# CBASS_CBASS_ISC_45820000h register map
Vendor: Texas Instruments
Peripheral module from a debugger description file (folder AM275x).
Registers are 32-bit, read-write, reset 0x0 unless marked. A register's access mark holds for its fields unless they carry their own. Offsets are as the file gives them; lines under a group give offsets from that group; [hi:lo] are bit positions; {n}, {i} and the like mark numbered series; 'fields as' and 'values as' point back to an identical list; <NAME> marks a mode.

## cbass_isc
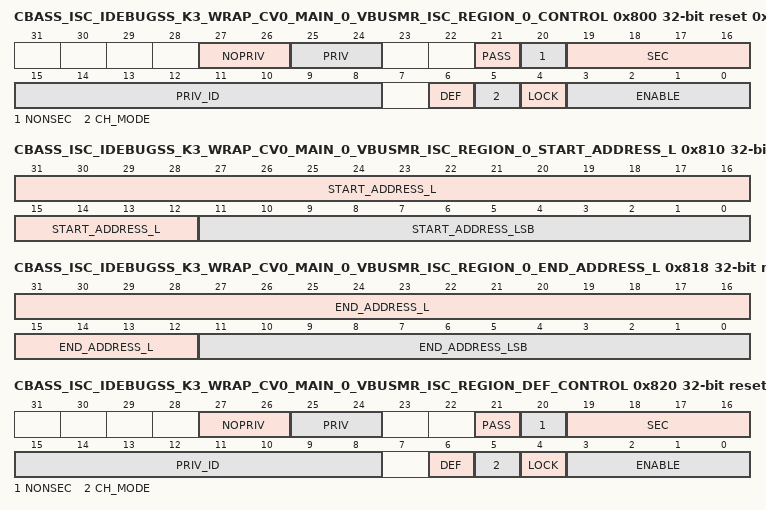
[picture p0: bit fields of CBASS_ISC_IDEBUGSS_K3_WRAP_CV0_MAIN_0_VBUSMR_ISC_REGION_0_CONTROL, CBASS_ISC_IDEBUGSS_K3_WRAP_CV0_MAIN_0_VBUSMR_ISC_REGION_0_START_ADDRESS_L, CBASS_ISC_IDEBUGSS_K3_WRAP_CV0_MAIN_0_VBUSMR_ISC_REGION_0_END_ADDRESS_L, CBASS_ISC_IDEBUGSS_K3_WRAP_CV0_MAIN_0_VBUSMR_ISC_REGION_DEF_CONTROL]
0x800 CBASS_ISC_IDEBUGSS_K3_WRAP_CV0_MAIN_0_VBUSMR_ISC_REGION_0_CONTROL access not given reset 0x10B100 — The ISC Region 0 Control Register defines the control fields for the initiator Idebugss_k3_wrap_cv0_main_0.vbusmr region 0 ISC.
  [27:26] NOPRIV rw — Clear output priv attribute. If each bit is set then the outgoing priv bit is cleared. Reset Source: domain_default_rst_mod_g_rst_n
  [25:24] PRIV rw — Set outgoing priv attribute. If each bit is set then the outgoing priv bit is set. Reset Source: domain_default_rst_mod_g_rst_n
  [21] PASS rw — No privID replacement, pass through value. Reset Source: domain_default_rst_mod_g_rst_n
  [20] NONSEC rw — Make outgoing non-secure. Reset Source: domain_default_rst_mod_g_rst_n
  [19:16] SEC rw — Make outgoing secure. A value of 0xA enables, others disable. Reset Source: domain_default_rst_mod_g_rst_n
  [15:8] PRIV_ID rw — Priv ID. Reset Source: domain_default_rst_mod_g_rst_n
  [6] DEF ro — Default region indication. The default region is used when all other regions do not match. Reset Source: domain_default_rst_mod_g_rst_n
  [5] CH_MODE rw — Enable channel mode to match region to a chanid value. Otherwise use address mode to match region to an address range. Reset Source: domain_default_rst_mod_g_rst_n
  [4] LOCK — Lock region. Once set the region values cannot be modified. Reset Source: domain_default_rst_mod_g_rst_n (access R/W1TS)
  [3:0] ENABLE rw — Enable region. A value of 0xA enables, others disable. Reset Source: domain_default_rst_mod_g_rst_n
0x810 CBASS_ISC_IDEBUGSS_K3_WRAP_CV0_MAIN_0_VBUSMR_ISC_REGION_0_START_ADDRESS_L — The ISC Region 0 Start Address Low Register defines the start address bits 31 to 0 for the initiator Idebugss_k3_wrap_cv0_main_0.vbusmr region 0 ISC.
  [31:12] START_ADDRESS_L — Start address bits 31 to 12. Reset Source: domain_default_rst_mod_g_rst_n
  [11:0] START_ADDRESS_LSB — Start address bits 11 to 0 must be 0 as address must be 4KB aligned in address mode. Can also be channel number in channel mode. Reset Source: domain_default_rst_mod_g_rst_n
0x814 CBASS_ISC_IDEBUGSS_K3_WRAP_CV0_MAIN_0_VBUSMR_ISC_REGION_0_START_ADDRESS_H — The ISC Region 0 Start Address High Register defines the start address bits 47 to 32 for the initiator Idebugss_k3_wrap_cv0_main_0.vbusmr region 0 ISC.
  [15:0] START_ADDRESS_H — Start address bits 47 to 32. Reset Source: domain_default_rst_mod_g_rst_n
0x818 CBASS_ISC_IDEBUGSS_K3_WRAP_CV0_MAIN_0_VBUSMR_ISC_REGION_0_END_ADDRESS_L access per field reset 0xFFF — The ISC Region 0 End Address Low Register defines the end included address bits 31 to 0 for the initiator Idebugss_k3_wrap_cv0_main_0.vbusmr region 0 ISC.
  [31:12] END_ADDRESS_L rw — End address bits 31 to 12 to include in the match. Reset Source: domain_default_rst_mod_g_rst_n
  [11:0] END_ADDRESS_LSB ro — End address bits 11 to 0 are forced to Fs as address must be 4KB aligned. Reset Source: domain_default_rst_mod_g_rst_n
0x81C CBASS_ISC_IDEBUGSS_K3_WRAP_CV0_MAIN_0_VBUSMR_ISC_REGION_0_END_ADDRESS_H — The ISC Region 0 End Address High Register defines the end address bits 47 to 32 for the initiator Idebugss_k3_wrap_cv0_main_0.vbusmr region 0 ISC.
  [15:0] END_ADDRESS_H — End address bits 47 to 32. Reset Source: domain_default_rst_mod_g_rst_n
0x820 CBASS_ISC_IDEBUGSS_K3_WRAP_CV0_MAIN_0_VBUSMR_ISC_REGION_DEF_CONTROL access not given reset 0x10B14A — The ISC Default Region Control Register defines the control fields for the initiator Idebugss_k3_wrap_cv0_main_0.vbusmr region 1 ISC.
  [27:26] NOPRIV rw — Clear output priv attribute. If each bit is set then the outgoing priv bit is cleared, else the bit is unchanged. Do not set both priv and nopriv for the same bit. Reset Source: domain_default_rst_mod_g_rst_n
  [25:24] PRIV rw — Set outgoing priv attribute. If each bit is set then the outgoing priv bit is set, else the bit is unchanged. Do not set both priv and nopriv for the same bit. Reset Source: domain_default_rst_mod_g_rst_n
  [21] PASS rw — No privID replacement. A value of 1 will pass through privid value. A value of 0 will replace privid with priv_id field value. Reset Source: domain_default_rst_mod_g_rst_n
  [20] NONSEC rw — Make outgoing non-secure. A value of 1 forces secure clear, others do nothing. Do not set both sec and nonsec. Reset Source: domain_default_rst_mod_g_rst_n
  [19:16] SEC rw — Make outgoing secure. A value of 0xA forces secure set, others do nothing. Do not set both sec and nonsec. Reset Source: domain_default_rst_mod_g_rst_n
  [15:8] PRIV_ID rw — Priv ID value to use if pass is 0. Reset Source: domain_default_rst_mod_g_rst_n
  [6] DEF ro — Default region indication. The default region is used when all other regions do not match. Reset Source: domain_default_rst_mod_g_rst_n
  [5] CH_MODE ro — Enable channel mode to match region to a chanid value. Otherwise use address mode to match region to an address range. Reset Source: domain_default_rst_mod_g_rst_n
  [4] LOCK — Lock region. Once set, the region values cannot be modified. Reset Source: domain_default_rst_mod_g_rst_n (access R/W1TS)
  [3:0] ENABLE ro — Enable region. A value of 0xA enables, others disable. Reset Source: domain_default_rst_mod_g_rst_n
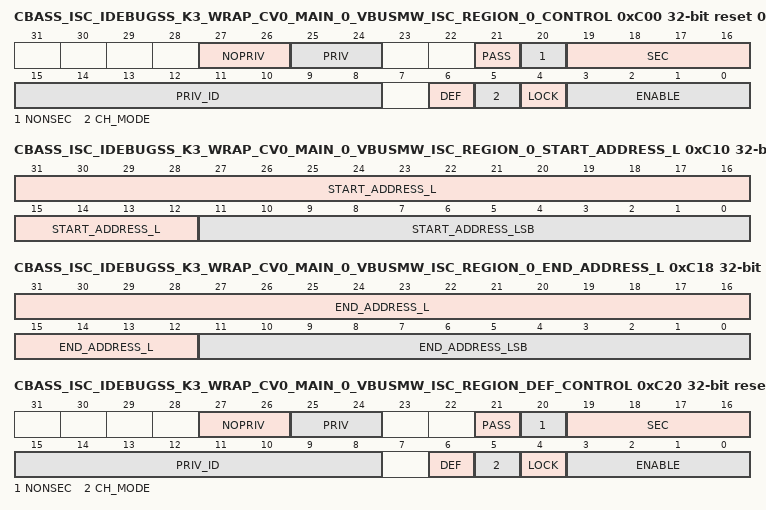
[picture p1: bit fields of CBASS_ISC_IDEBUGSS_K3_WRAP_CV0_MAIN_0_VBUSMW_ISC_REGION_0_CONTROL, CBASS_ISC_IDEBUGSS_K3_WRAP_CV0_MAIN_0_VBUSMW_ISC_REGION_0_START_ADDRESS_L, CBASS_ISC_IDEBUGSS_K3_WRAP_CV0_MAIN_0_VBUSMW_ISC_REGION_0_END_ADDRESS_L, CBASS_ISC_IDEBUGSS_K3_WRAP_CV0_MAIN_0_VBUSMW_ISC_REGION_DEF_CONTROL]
0xC00 CBASS_ISC_IDEBUGSS_K3_WRAP_CV0_MAIN_0_VBUSMW_ISC_REGION_0_CONTROL access not given reset 0x10B100 — The ISC Region 0 Control Register defines the control fields for the initiator Idebugss_k3_wrap_cv0_main_0.vbusmw region 0 ISC.
  fields as CBASS_ISC_IDEBUGSS_K3_WRAP_CV0_MAIN_0_VBUSMR_ISC_REGION_0_CONTROL
0xC10 CBASS_ISC_IDEBUGSS_K3_WRAP_CV0_MAIN_0_VBUSMW_ISC_REGION_0_START_ADDRESS_L — The ISC Region 0 Start Address Low Register defines the start address bits 31 to 0 for the initiator Idebugss_k3_wrap_cv0_main_0.vbusmw region 0 ISC.
  fields as CBASS_ISC_IDEBUGSS_K3_WRAP_CV0_MAIN_0_VBUSMR_ISC_REGION_0_START_ADDRESS_L
0xC14 CBASS_ISC_IDEBUGSS_K3_WRAP_CV0_MAIN_0_VBUSMW_ISC_REGION_0_START_ADDRESS_H — The ISC Region 0 Start Address High Register defines the start address bits 47 to 32 for the initiator Idebugss_k3_wrap_cv0_main_0.vbusmw region 0 ISC.
  fields as CBASS_ISC_IDEBUGSS_K3_WRAP_CV0_MAIN_0_VBUSMR_ISC_REGION_0_START_ADDRESS_H
0xC18 CBASS_ISC_IDEBUGSS_K3_WRAP_CV0_MAIN_0_VBUSMW_ISC_REGION_0_END_ADDRESS_L access per field reset 0xFFF — The ISC Region 0 End Address Low Register defines the end included address bits 31 to 0 for the initiator Idebugss_k3_wrap_cv0_main_0.vbusmw region 0 ISC.
  fields as CBASS_ISC_IDEBUGSS_K3_WRAP_CV0_MAIN_0_VBUSMR_ISC_REGION_0_END_ADDRESS_L
0xC1C CBASS_ISC_IDEBUGSS_K3_WRAP_CV0_MAIN_0_VBUSMW_ISC_REGION_0_END_ADDRESS_H — The ISC Region 0 End Address High Register defines the end address bits 47 to 32 for the initiator Idebugss_k3_wrap_cv0_main_0.vbusmw region 0 ISC.
  fields as CBASS_ISC_IDEBUGSS_K3_WRAP_CV0_MAIN_0_VBUSMR_ISC_REGION_0_END_ADDRESS_H
0xC20 CBASS_ISC_IDEBUGSS_K3_WRAP_CV0_MAIN_0_VBUSMW_ISC_REGION_DEF_CONTROL access not given reset 0x10B14A — The ISC Default Region Control Register defines the control fields for the initiator Idebugss_k3_wrap_cv0_main_0.vbusmw region 1 ISC.
  fields as CBASS_ISC_IDEBUGSS_K3_WRAP_CV0_MAIN_0_VBUSMR_ISC_REGION_DEF_CONTROL
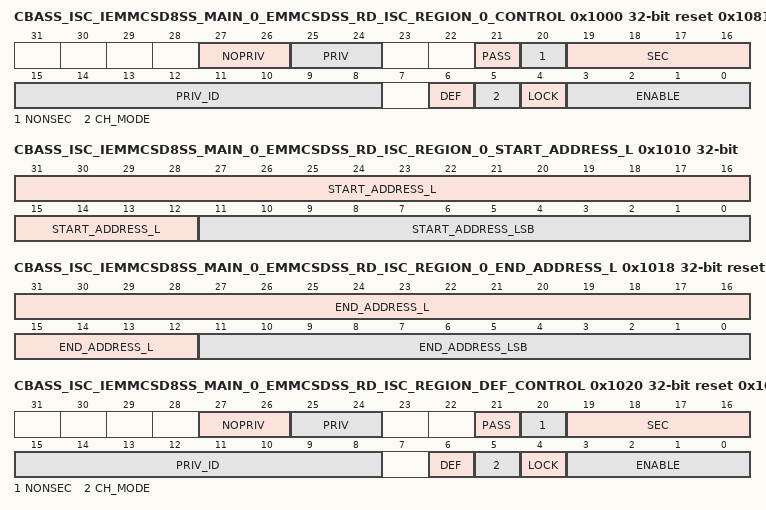
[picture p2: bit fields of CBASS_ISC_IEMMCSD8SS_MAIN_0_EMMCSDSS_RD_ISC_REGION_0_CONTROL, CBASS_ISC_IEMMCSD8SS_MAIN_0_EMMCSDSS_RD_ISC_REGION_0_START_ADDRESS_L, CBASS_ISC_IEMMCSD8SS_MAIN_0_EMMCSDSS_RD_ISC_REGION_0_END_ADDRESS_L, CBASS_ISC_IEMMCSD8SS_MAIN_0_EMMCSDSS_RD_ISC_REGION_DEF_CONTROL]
0x1000 CBASS_ISC_IEMMCSD8SS_MAIN_0_EMMCSDSS_RD_ISC_REGION_0_CONTROL access not given reset 0x108100 — The ISC Region 0 Control Register defines the control fields for the initiator Iemmcsd8ss_main_0.emmcsdss_rd region 0 ISC.
  fields as CBASS_ISC_IDEBUGSS_K3_WRAP_CV0_MAIN_0_VBUSMR_ISC_REGION_0_CONTROL
0x1010 CBASS_ISC_IEMMCSD8SS_MAIN_0_EMMCSDSS_RD_ISC_REGION_0_START_ADDRESS_L — The ISC Region 0 Start Address Low Register defines the start address bits 31 to 0 for the initiator Iemmcsd8ss_main_0.emmcsdss_rd region 0 ISC.
  fields as CBASS_ISC_IDEBUGSS_K3_WRAP_CV0_MAIN_0_VBUSMR_ISC_REGION_0_START_ADDRESS_L
0x1014 CBASS_ISC_IEMMCSD8SS_MAIN_0_EMMCSDSS_RD_ISC_REGION_0_START_ADDRESS_H — The ISC Region 0 Start Address High Register defines the start address bits 47 to 32 for the initiator Iemmcsd8ss_main_0.emmcsdss_rd region 0 ISC.
  fields as CBASS_ISC_IDEBUGSS_K3_WRAP_CV0_MAIN_0_VBUSMR_ISC_REGION_0_START_ADDRESS_H
0x1018 CBASS_ISC_IEMMCSD8SS_MAIN_0_EMMCSDSS_RD_ISC_REGION_0_END_ADDRESS_L access per field reset 0xFFF — The ISC Region 0 End Address Low Register defines the end included address bits 31 to 0 for the initiator Iemmcsd8ss_main_0.emmcsdss_rd region 0 ISC.
  fields as CBASS_ISC_IDEBUGSS_K3_WRAP_CV0_MAIN_0_VBUSMR_ISC_REGION_0_END_ADDRESS_L
0x101C CBASS_ISC_IEMMCSD8SS_MAIN_0_EMMCSDSS_RD_ISC_REGION_0_END_ADDRESS_H — The ISC Region 0 End Address High Register defines the end address bits 47 to 32 for the initiator Iemmcsd8ss_main_0.emmcsdss_rd region 0 ISC.
  fields as CBASS_ISC_IDEBUGSS_K3_WRAP_CV0_MAIN_0_VBUSMR_ISC_REGION_0_END_ADDRESS_H
0x1020 CBASS_ISC_IEMMCSD8SS_MAIN_0_EMMCSDSS_RD_ISC_REGION_DEF_CONTROL access not given reset 0x10814A — The ISC Default Region Control Register defines the control fields for the initiator Iemmcsd8ss_main_0.emmcsdss_rd region 1 ISC.
  fields as CBASS_ISC_IDEBUGSS_K3_WRAP_CV0_MAIN_0_VBUSMR_ISC_REGION_DEF_CONTROL
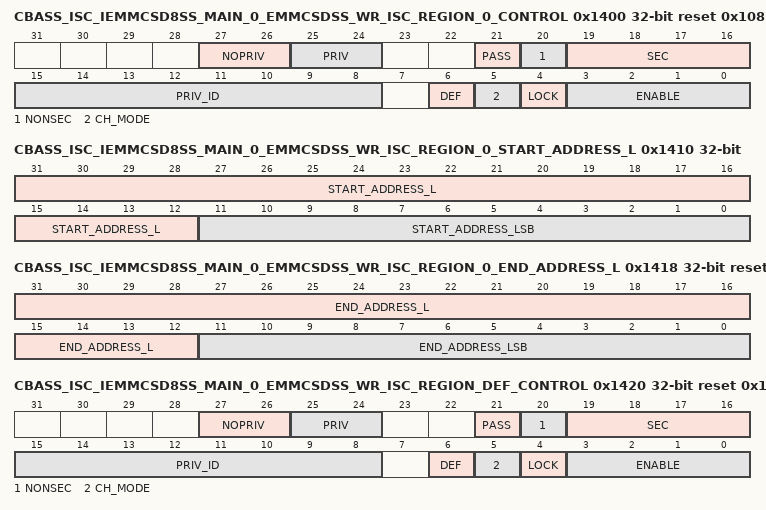
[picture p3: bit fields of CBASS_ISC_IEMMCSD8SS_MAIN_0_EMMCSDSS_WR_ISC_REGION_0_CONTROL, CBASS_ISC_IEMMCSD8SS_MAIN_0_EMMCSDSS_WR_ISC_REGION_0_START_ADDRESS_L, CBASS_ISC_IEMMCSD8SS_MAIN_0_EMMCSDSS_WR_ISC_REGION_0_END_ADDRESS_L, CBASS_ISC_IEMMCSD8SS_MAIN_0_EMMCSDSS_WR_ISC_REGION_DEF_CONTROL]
0x1400 CBASS_ISC_IEMMCSD8SS_MAIN_0_EMMCSDSS_WR_ISC_REGION_0_CONTROL access not given reset 0x108100 — The ISC Region 0 Control Register defines the control fields for the initiator Iemmcsd8ss_main_0.emmcsdss_wr region 0 ISC.
  fields as CBASS_ISC_IDEBUGSS_K3_WRAP_CV0_MAIN_0_VBUSMR_ISC_REGION_0_CONTROL
0x1410 CBASS_ISC_IEMMCSD8SS_MAIN_0_EMMCSDSS_WR_ISC_REGION_0_START_ADDRESS_L — The ISC Region 0 Start Address Low Register defines the start address bits 31 to 0 for the initiator Iemmcsd8ss_main_0.emmcsdss_wr region 0 ISC.
  fields as CBASS_ISC_IDEBUGSS_K3_WRAP_CV0_MAIN_0_VBUSMR_ISC_REGION_0_START_ADDRESS_L
0x1414 CBASS_ISC_IEMMCSD8SS_MAIN_0_EMMCSDSS_WR_ISC_REGION_0_START_ADDRESS_H — The ISC Region 0 Start Address High Register defines the start address bits 47 to 32 for the initiator Iemmcsd8ss_main_0.emmcsdss_wr region 0 ISC.
  fields as CBASS_ISC_IDEBUGSS_K3_WRAP_CV0_MAIN_0_VBUSMR_ISC_REGION_0_START_ADDRESS_H
0x1418 CBASS_ISC_IEMMCSD8SS_MAIN_0_EMMCSDSS_WR_ISC_REGION_0_END_ADDRESS_L access per field reset 0xFFF — The ISC Region 0 End Address Low Register defines the end included address bits 31 to 0 for the initiator Iemmcsd8ss_main_0.emmcsdss_wr region 0 ISC.
  fields as CBASS_ISC_IDEBUGSS_K3_WRAP_CV0_MAIN_0_VBUSMR_ISC_REGION_0_END_ADDRESS_L
0x141C CBASS_ISC_IEMMCSD8SS_MAIN_0_EMMCSDSS_WR_ISC_REGION_0_END_ADDRESS_H — The ISC Region 0 End Address High Register defines the end address bits 47 to 32 for the initiator Iemmcsd8ss_main_0.emmcsdss_wr region 0 ISC.
  fields as CBASS_ISC_IDEBUGSS_K3_WRAP_CV0_MAIN_0_VBUSMR_ISC_REGION_0_END_ADDRESS_H
0x1420 CBASS_ISC_IEMMCSD8SS_MAIN_0_EMMCSDSS_WR_ISC_REGION_DEF_CONTROL access not given reset 0x10814A — The ISC Default Region Control Register defines the control fields for the initiator Iemmcsd8ss_main_0.emmcsdss_wr region 1 ISC.
  fields as CBASS_ISC_IDEBUGSS_K3_WRAP_CV0_MAIN_0_VBUSMR_ISC_REGION_DEF_CONTROL
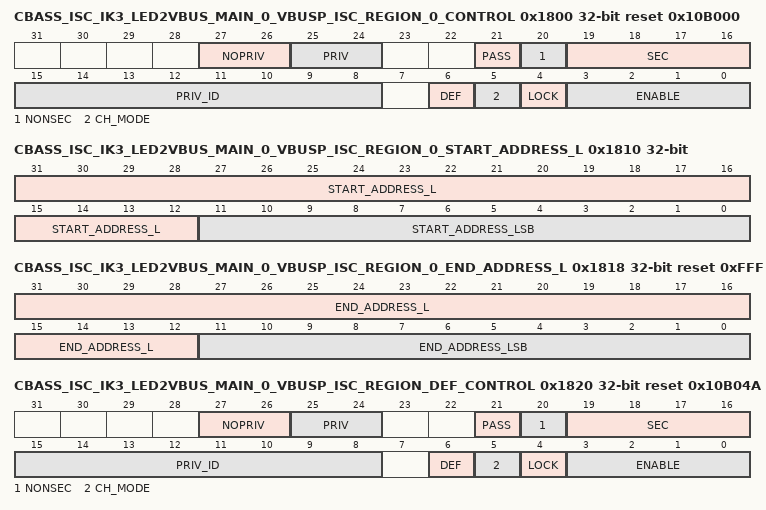
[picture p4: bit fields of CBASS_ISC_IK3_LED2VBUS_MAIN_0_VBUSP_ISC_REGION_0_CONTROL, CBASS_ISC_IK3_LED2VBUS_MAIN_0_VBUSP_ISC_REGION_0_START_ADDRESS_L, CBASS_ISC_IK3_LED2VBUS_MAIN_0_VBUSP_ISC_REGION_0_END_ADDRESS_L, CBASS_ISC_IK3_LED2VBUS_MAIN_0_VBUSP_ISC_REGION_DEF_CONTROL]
0x1800 CBASS_ISC_IK3_LED2VBUS_MAIN_0_VBUSP_ISC_REGION_0_CONTROL access not given reset 0x10B000 — The ISC Region 0 Control Register defines the control fields for the initiator Ik3_led2vbus_main_0.vbusp region 0 ISC.
  fields as CBASS_ISC_IDEBUGSS_K3_WRAP_CV0_MAIN_0_VBUSMR_ISC_REGION_0_CONTROL
0x1810 CBASS_ISC_IK3_LED2VBUS_MAIN_0_VBUSP_ISC_REGION_0_START_ADDRESS_L — The ISC Region 0 Start Address Low Register defines the start address bits 31 to 0 for the initiator Ik3_led2vbus_main_0.vbusp region 0 ISC.
  fields as CBASS_ISC_IDEBUGSS_K3_WRAP_CV0_MAIN_0_VBUSMR_ISC_REGION_0_START_ADDRESS_L
0x1814 CBASS_ISC_IK3_LED2VBUS_MAIN_0_VBUSP_ISC_REGION_0_START_ADDRESS_H — The ISC Region 0 Start Address High Register defines the start address bits 47 to 32 for the initiator Ik3_led2vbus_main_0.vbusp region 0 ISC.
  fields as CBASS_ISC_IDEBUGSS_K3_WRAP_CV0_MAIN_0_VBUSMR_ISC_REGION_0_START_ADDRESS_H
0x1818 CBASS_ISC_IK3_LED2VBUS_MAIN_0_VBUSP_ISC_REGION_0_END_ADDRESS_L access per field reset 0xFFF — The ISC Region 0 End Address Low Register defines the end included address bits 31 to 0 for the initiator Ik3_led2vbus_main_0.vbusp region 0 ISC.
  fields as CBASS_ISC_IDEBUGSS_K3_WRAP_CV0_MAIN_0_VBUSMR_ISC_REGION_0_END_ADDRESS_L
0x181C CBASS_ISC_IK3_LED2VBUS_MAIN_0_VBUSP_ISC_REGION_0_END_ADDRESS_H — The ISC Region 0 End Address High Register defines the end address bits 47 to 32 for the initiator Ik3_led2vbus_main_0.vbusp region 0 ISC.
  fields as CBASS_ISC_IDEBUGSS_K3_WRAP_CV0_MAIN_0_VBUSMR_ISC_REGION_0_END_ADDRESS_H
0x1820 CBASS_ISC_IK3_LED2VBUS_MAIN_0_VBUSP_ISC_REGION_DEF_CONTROL access not given reset 0x10B04A — The ISC Default Region Control Register defines the control fields for the initiator Ik3_led2vbus_main_0.vbusp region 1 ISC.
  fields as CBASS_ISC_IDEBUGSS_K3_WRAP_CV0_MAIN_0_VBUSMR_ISC_REGION_DEF_CONTROL
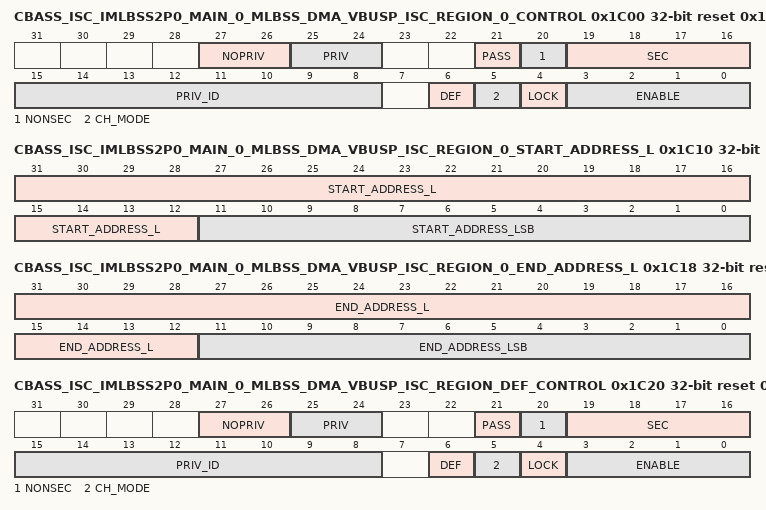
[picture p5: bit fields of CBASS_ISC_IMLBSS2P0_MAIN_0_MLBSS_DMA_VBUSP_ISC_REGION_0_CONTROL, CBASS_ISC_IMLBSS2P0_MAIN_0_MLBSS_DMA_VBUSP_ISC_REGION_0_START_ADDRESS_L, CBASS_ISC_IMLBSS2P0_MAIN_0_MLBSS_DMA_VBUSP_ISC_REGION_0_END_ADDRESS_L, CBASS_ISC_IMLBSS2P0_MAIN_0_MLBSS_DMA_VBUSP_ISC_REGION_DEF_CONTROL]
0x1C00 CBASS_ISC_IMLBSS2P0_MAIN_0_MLBSS_DMA_VBUSP_ISC_REGION_0_CONTROL access not given reset 0x108200 — The ISC Region 0 Control Register defines the control fields for the initiator Imlbss2p0_main_0.mlbss_dma_vbusp region 0 ISC.
  fields as CBASS_ISC_IDEBUGSS_K3_WRAP_CV0_MAIN_0_VBUSMR_ISC_REGION_0_CONTROL
0x1C10 CBASS_ISC_IMLBSS2P0_MAIN_0_MLBSS_DMA_VBUSP_ISC_REGION_0_START_ADDRESS_L — The ISC Region 0 Start Address Low Register defines the start address bits 31 to 0 for the initiator Imlbss2p0_main_0.mlbss_dma_vbusp region 0 ISC.
  fields as CBASS_ISC_IDEBUGSS_K3_WRAP_CV0_MAIN_0_VBUSMR_ISC_REGION_0_START_ADDRESS_L
0x1C14 CBASS_ISC_IMLBSS2P0_MAIN_0_MLBSS_DMA_VBUSP_ISC_REGION_0_START_ADDRESS_H — The ISC Region 0 Start Address High Register defines the start address bits 47 to 32 for the initiator Imlbss2p0_main_0.mlbss_dma_vbusp region 0 ISC.
  fields as CBASS_ISC_IDEBUGSS_K3_WRAP_CV0_MAIN_0_VBUSMR_ISC_REGION_0_START_ADDRESS_H
0x1C18 CBASS_ISC_IMLBSS2P0_MAIN_0_MLBSS_DMA_VBUSP_ISC_REGION_0_END_ADDRESS_L access per field reset 0xFFF — The ISC Region 0 End Address Low Register defines the end included address bits 31 to 0 for the initiator Imlbss2p0_main_0.mlbss_dma_vbusp region 0 ISC.
  fields as CBASS_ISC_IDEBUGSS_K3_WRAP_CV0_MAIN_0_VBUSMR_ISC_REGION_0_END_ADDRESS_L
0x1C1C CBASS_ISC_IMLBSS2P0_MAIN_0_MLBSS_DMA_VBUSP_ISC_REGION_0_END_ADDRESS_H — The ISC Region 0 End Address High Register defines the end address bits 47 to 32 for the initiator Imlbss2p0_main_0.mlbss_dma_vbusp region 0 ISC.
  fields as CBASS_ISC_IDEBUGSS_K3_WRAP_CV0_MAIN_0_VBUSMR_ISC_REGION_0_END_ADDRESS_H
0x1C20 CBASS_ISC_IMLBSS2P0_MAIN_0_MLBSS_DMA_VBUSP_ISC_REGION_DEF_CONTROL access not given reset 0x10824A — The ISC Default Region Control Register defines the control fields for the initiator Imlbss2p0_main_0.mlbss_dma_vbusp region 1 ISC.
  fields as CBASS_ISC_IDEBUGSS_K3_WRAP_CV0_MAIN_0_VBUSMR_ISC_REGION_DEF_CONTROL
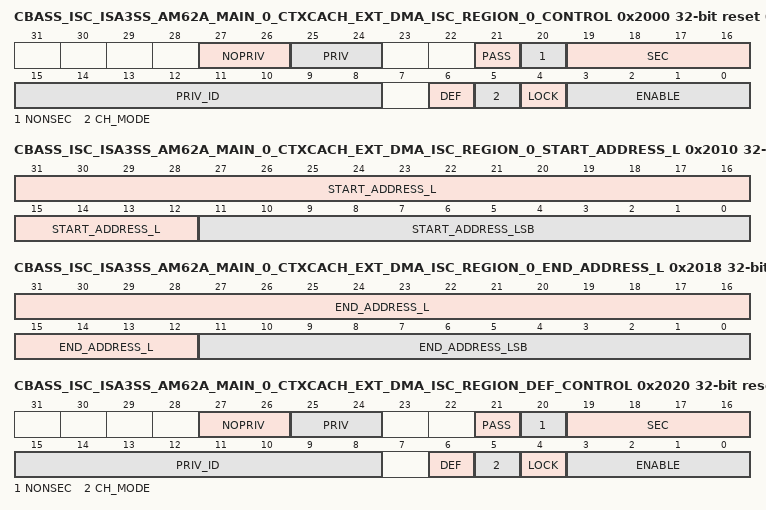
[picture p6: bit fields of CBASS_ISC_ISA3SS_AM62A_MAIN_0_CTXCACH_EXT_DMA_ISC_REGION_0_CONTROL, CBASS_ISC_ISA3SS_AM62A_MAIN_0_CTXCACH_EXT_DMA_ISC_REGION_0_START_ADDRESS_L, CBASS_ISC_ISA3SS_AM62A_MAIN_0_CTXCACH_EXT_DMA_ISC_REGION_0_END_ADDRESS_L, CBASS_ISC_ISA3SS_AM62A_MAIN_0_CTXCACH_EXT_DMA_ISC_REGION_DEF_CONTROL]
0x2000 CBASS_ISC_ISA3SS_AM62A_MAIN_0_CTXCACH_EXT_DMA_ISC_REGION_0_CONTROL access not given reset 0x109800 — The ISC Region 0 Control Register defines the control fields for the initiator Isa3ss_am62a_main_0.ctxcach_ext_dma region 0 ISC.
  fields as CBASS_ISC_IDEBUGSS_K3_WRAP_CV0_MAIN_0_VBUSMR_ISC_REGION_0_CONTROL
0x2010 CBASS_ISC_ISA3SS_AM62A_MAIN_0_CTXCACH_EXT_DMA_ISC_REGION_0_START_ADDRESS_L — The ISC Region 0 Start Address Low Register defines the start address bits 31 to 0 for the initiator Isa3ss_am62a_main_0.ctxcach_ext_dma region 0 ISC.
  fields as CBASS_ISC_IDEBUGSS_K3_WRAP_CV0_MAIN_0_VBUSMR_ISC_REGION_0_START_ADDRESS_L
0x2014 CBASS_ISC_ISA3SS_AM62A_MAIN_0_CTXCACH_EXT_DMA_ISC_REGION_0_START_ADDRESS_H — The ISC Region 0 Start Address High Register defines the start address bits 47 to 32 for the initiator Isa3ss_am62a_main_0.ctxcach_ext_dma region 0 ISC.
  fields as CBASS_ISC_IDEBUGSS_K3_WRAP_CV0_MAIN_0_VBUSMR_ISC_REGION_0_START_ADDRESS_H
0x2018 CBASS_ISC_ISA3SS_AM62A_MAIN_0_CTXCACH_EXT_DMA_ISC_REGION_0_END_ADDRESS_L access per field reset 0xFFF — The ISC Region 0 End Address Low Register defines the end included address bits 31 to 0 for the initiator Isa3ss_am62a_main_0.ctxcach_ext_dma region 0 ISC.
  fields as CBASS_ISC_IDEBUGSS_K3_WRAP_CV0_MAIN_0_VBUSMR_ISC_REGION_0_END_ADDRESS_L
0x201C CBASS_ISC_ISA3SS_AM62A_MAIN_0_CTXCACH_EXT_DMA_ISC_REGION_0_END_ADDRESS_H — The ISC Region 0 End Address High Register defines the end address bits 47 to 32 for the initiator Isa3ss_am62a_main_0.ctxcach_ext_dma region 0 ISC.
  fields as CBASS_ISC_IDEBUGSS_K3_WRAP_CV0_MAIN_0_VBUSMR_ISC_REGION_0_END_ADDRESS_H
0x2020 CBASS_ISC_ISA3SS_AM62A_MAIN_0_CTXCACH_EXT_DMA_ISC_REGION_DEF_CONTROL access not given reset 0x10984A — The ISC Default Region Control Register defines the control fields for the initiator Isa3ss_am62a_main_0.ctxcach_ext_dma region 1 ISC.
  fields as CBASS_ISC_IDEBUGSS_K3_WRAP_CV0_MAIN_0_VBUSMR_ISC_REGION_DEF_CONTROL
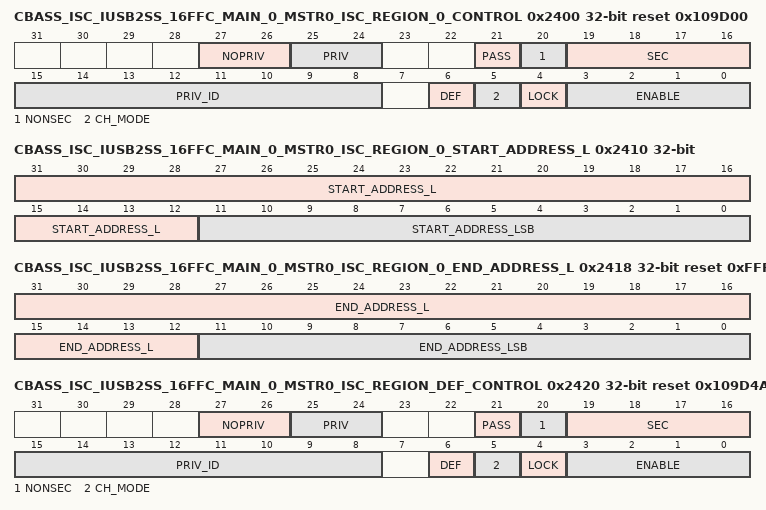
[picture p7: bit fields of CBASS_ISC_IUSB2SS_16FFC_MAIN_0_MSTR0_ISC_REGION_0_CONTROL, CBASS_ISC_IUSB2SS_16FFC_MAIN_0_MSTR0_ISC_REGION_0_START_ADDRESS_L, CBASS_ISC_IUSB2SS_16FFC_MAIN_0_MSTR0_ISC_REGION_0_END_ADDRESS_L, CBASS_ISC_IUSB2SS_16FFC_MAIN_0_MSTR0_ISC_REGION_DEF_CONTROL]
0x2400 CBASS_ISC_IUSB2SS_16FFC_MAIN_0_MSTR0_ISC_REGION_0_CONTROL access not given reset 0x109D00 — The ISC Region 0 Control Register defines the control fields for the initiator Iusb2ss_16ffc_main_0.mstr0 region 0 ISC.
  fields as CBASS_ISC_IDEBUGSS_K3_WRAP_CV0_MAIN_0_VBUSMR_ISC_REGION_0_CONTROL
0x2410 CBASS_ISC_IUSB2SS_16FFC_MAIN_0_MSTR0_ISC_REGION_0_START_ADDRESS_L — The ISC Region 0 Start Address Low Register defines the start address bits 31 to 0 for the initiator Iusb2ss_16ffc_main_0.mstr0 region 0 ISC.
  fields as CBASS_ISC_IDEBUGSS_K3_WRAP_CV0_MAIN_0_VBUSMR_ISC_REGION_0_START_ADDRESS_L
0x2414 CBASS_ISC_IUSB2SS_16FFC_MAIN_0_MSTR0_ISC_REGION_0_START_ADDRESS_H — The ISC Region 0 Start Address High Register defines the start address bits 47 to 32 for the initiator Iusb2ss_16ffc_main_0.mstr0 region 0 ISC.
  fields as CBASS_ISC_IDEBUGSS_K3_WRAP_CV0_MAIN_0_VBUSMR_ISC_REGION_0_START_ADDRESS_H
0x2418 CBASS_ISC_IUSB2SS_16FFC_MAIN_0_MSTR0_ISC_REGION_0_END_ADDRESS_L access per field reset 0xFFF — The ISC Region 0 End Address Low Register defines the end included address bits 31 to 0 for the initiator Iusb2ss_16ffc_main_0.mstr0 region 0 ISC.
  fields as CBASS_ISC_IDEBUGSS_K3_WRAP_CV0_MAIN_0_VBUSMR_ISC_REGION_0_END_ADDRESS_L
0x241C CBASS_ISC_IUSB2SS_16FFC_MAIN_0_MSTR0_ISC_REGION_0_END_ADDRESS_H — The ISC Region 0 End Address High Register defines the end address bits 47 to 32 for the initiator Iusb2ss_16ffc_main_0.mstr0 region 0 ISC.
  fields as CBASS_ISC_IDEBUGSS_K3_WRAP_CV0_MAIN_0_VBUSMR_ISC_REGION_0_END_ADDRESS_H
0x2420 CBASS_ISC_IUSB2SS_16FFC_MAIN_0_MSTR0_ISC_REGION_DEF_CONTROL access not given reset 0x109D4A — The ISC Default Region Control Register defines the control fields for the initiator Iusb2ss_16ffc_main_0.mstr0 region 1 ISC.
  fields as CBASS_ISC_IDEBUGSS_K3_WRAP_CV0_MAIN_0_VBUSMR_ISC_REGION_DEF_CONTROL
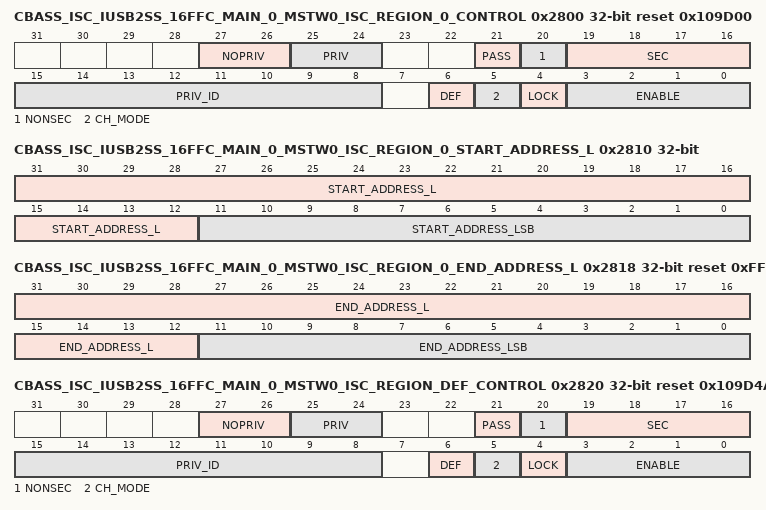
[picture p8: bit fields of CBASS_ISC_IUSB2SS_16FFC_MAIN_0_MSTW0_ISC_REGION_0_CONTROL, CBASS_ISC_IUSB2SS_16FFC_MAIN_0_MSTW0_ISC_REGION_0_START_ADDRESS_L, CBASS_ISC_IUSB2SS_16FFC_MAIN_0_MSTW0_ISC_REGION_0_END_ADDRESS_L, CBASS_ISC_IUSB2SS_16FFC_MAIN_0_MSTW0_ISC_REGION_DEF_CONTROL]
0x2800 CBASS_ISC_IUSB2SS_16FFC_MAIN_0_MSTW0_ISC_REGION_0_CONTROL access not given reset 0x109D00 — The ISC Region 0 Control Register defines the control fields for the initiator Iusb2ss_16ffc_main_0.mstw0 region 0 ISC.
  fields as CBASS_ISC_IDEBUGSS_K3_WRAP_CV0_MAIN_0_VBUSMR_ISC_REGION_0_CONTROL
0x2810 CBASS_ISC_IUSB2SS_16FFC_MAIN_0_MSTW0_ISC_REGION_0_START_ADDRESS_L — The ISC Region 0 Start Address Low Register defines the start address bits 31 to 0 for the initiator Iusb2ss_16ffc_main_0.mstw0 region 0 ISC.
  fields as CBASS_ISC_IDEBUGSS_K3_WRAP_CV0_MAIN_0_VBUSMR_ISC_REGION_0_START_ADDRESS_L
0x2814 CBASS_ISC_IUSB2SS_16FFC_MAIN_0_MSTW0_ISC_REGION_0_START_ADDRESS_H — The ISC Region 0 Start Address High Register defines the start address bits 47 to 32 for the initiator Iusb2ss_16ffc_main_0.mstw0 region 0 ISC.
  fields as CBASS_ISC_IDEBUGSS_K3_WRAP_CV0_MAIN_0_VBUSMR_ISC_REGION_0_START_ADDRESS_H
0x2818 CBASS_ISC_IUSB2SS_16FFC_MAIN_0_MSTW0_ISC_REGION_0_END_ADDRESS_L access per field reset 0xFFF — The ISC Region 0 End Address Low Register defines the end included address bits 31 to 0 for the initiator Iusb2ss_16ffc_main_0.mstw0 region 0 ISC.
  fields as CBASS_ISC_IDEBUGSS_K3_WRAP_CV0_MAIN_0_VBUSMR_ISC_REGION_0_END_ADDRESS_L
0x281C CBASS_ISC_IUSB2SS_16FFC_MAIN_0_MSTW0_ISC_REGION_0_END_ADDRESS_H — The ISC Region 0 End Address High Register defines the end address bits 47 to 32 for the initiator Iusb2ss_16ffc_main_0.mstw0 region 0 ISC.
  fields as CBASS_ISC_IDEBUGSS_K3_WRAP_CV0_MAIN_0_VBUSMR_ISC_REGION_0_END_ADDRESS_H
0x2820 CBASS_ISC_IUSB2SS_16FFC_MAIN_0_MSTW0_ISC_REGION_DEF_CONTROL access not given reset 0x109D4A — The ISC Default Region Control Register defines the control fields for the initiator Iusb2ss_16ffc_main_0.mstw0 region 1 ISC.
  fields as CBASS_ISC_IDEBUGSS_K3_WRAP_CV0_MAIN_0_VBUSMR_ISC_REGION_DEF_CONTROL
